AUTOSAR XML (schema 00046)
package /ComponentTypes
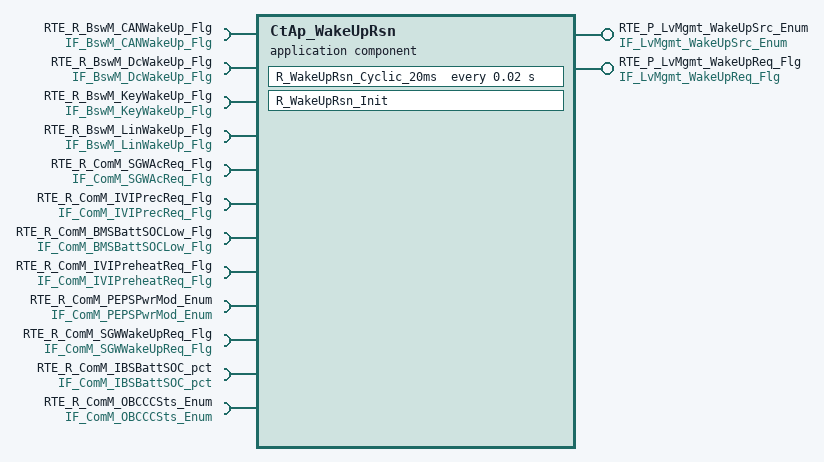
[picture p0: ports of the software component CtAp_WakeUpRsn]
  application sw component type CtAp_WakeUpRsn
    12 x require port:
      RTE_R_BswM_CANWakeUp_Flg: nonqueued-receiver-com-spec{data-element=tec_BswM_CANWakeUp_Flg, filter=data-filter-type=ALWAYS, init-value=0}, required-interface=IF_BswM_CANWakeUp_Flg
      RTE_R_BswM_DcWakeUp_Flg: nonqueued-receiver-com-spec{data-element=tec_BswM_DcWakeUp_Flg, filter=data-filter-type=ALWAYS, init-value=0}, required-interface=IF_BswM_DcWakeUp_Flg
      RTE_R_BswM_KeyWakeUp_Flg: nonqueued-receiver-com-spec{data-element=tec_BswM_KeyWakeUp_Flg, filter=data-filter-type=ALWAYS, init-value=0}, required-interface=IF_BswM_KeyWakeUp_Flg
      RTE_R_BswM_LinWakeUp_Flg: nonqueued-receiver-com-spec{data-element=tec_BswM_LinWakeUp_Flg, filter=data-filter-type=ALWAYS, init-value=0}, required-interface=IF_BswM_LinWakeUp_Flg
      RTE_R_ComM_SGWAcReq_Flg: nonqueued-receiver-com-spec{data-element=tec_ComM_SGWAcReq_Flg, filter=data-filter-type=ALWAYS, init-value=0}, required-interface=IF_ComM_SGWAcReq_Flg
      RTE_R_ComM_IVIPrecReq_Flg: nonqueued-receiver-com-spec{data-element=tec_ComM_IVIPrecReq_Flg, filter=data-filter-type=ALWAYS, init-value=0}, required-interface=IF_ComM_IVIPrecReq_Flg
      RTE_R_ComM_BMSBattSOCLow_Flg: nonqueued-receiver-com-spec{data-element=tec_ComM_BMSBattSOCLow_Flg, filter=data-filter-type=ALWAYS, init-value=0}, required-interface=IF_ComM_BMSBattSOCLow_Flg
      RTE_R_ComM_IVIPreheatReq_Flg: nonqueued-receiver-com-spec{data-element=tec_ComM_IVIPreheatReq_Flg, filter=data-filter-type=ALWAYS, init-value=0}, required-interface=IF_ComM_IVIPreheatReq_Flg
      RTE_R_ComM_PEPSPwrMod_Enum: nonqueued-receiver-com-spec{data-element=tec_ComM_PEPSPwrMod_Enum, filter=data-filter-type=ALWAYS, init-value=0}, required-interface=IF_ComM_PEPSPwrMod_Enum
      RTE_R_ComM_SGWWakeUpReq_Flg: nonqueued-receiver-com-spec{data-element=tec_ComM_SGWWakeUpReq_Flg, filter=data-filter-type=ALWAYS, init-value=0}, required-interface=IF_ComM_SGWWakeUpReq_Flg
      RTE_R_ComM_IBSBattSOC_pct: nonqueued-receiver-com-spec{data-element=tec_ComM_IBSBattSOC_pct, filter=data-filter-type=ALWAYS, init-value=0}, required-interface=IF_ComM_IBSBattSOC_pct
      RTE_R_ComM_OBCCCSts_Enum: nonqueued-receiver-com-spec{data-element=tec_ComM_OBCCCSts_Enum, filter=data-filter-type=ALWAYS, init-value=0}, required-interface=IF_ComM_OBCCCSts_Enum
    provide port RTE_P_LvMgmt_WakeUpSrc_Enum: nonqueued-sender-com-spec{data-element=tec_LvMgmt_WakeUpSrc_Enum, init-value=0}, provided-interface=IF_LvMgmt_WakeUpSrc_Enum
    provide port RTE_P_LvMgmt_WakeUpReq_Flg: nonqueued-sender-com-spec{data-element=tec_LvMgmt_WakeUpReq_Flg, init-value=0}, provided-interface=IF_LvMgmt_WakeUpReq_Flg
    behavior CtAp_WakeUpRsn_InternalBehavior
      init event CtAp_WakeUpRsn_InitEvent: start-on-event=R_WakeUpRsn_Init
      timing event TMT_R_WakeUpRsn_Cyclic_20ms: start-on-event=R_WakeUpRsn_Cyclic_20ms, period=0.02
      runnable R_WakeUpRsn_Init
      runnable R_WakeUpRsn_Cyclic_20ms
        data-receive-point-by-arguments:
          12 x access:
            REC_RTE_R_BswM_CANWakeUp_Flg_tec_BswM_CANWakeUp_Flg: accessed-variable=RTE_R_BswM_CANWakeUp_Flg.tec_BswM_CANWakeUp_Flg
            REC_RTE_R_BswM_DcWakeUp_Flg_tec_BswM_DcWakeUp_Flg: accessed-variable=RTE_R_BswM_DcWakeUp_Flg.tec_BswM_DcWakeUp_Flg
            REC_RTE_R_BswM_KeyWakeUp_Flg_tec_BswM_KeyWakeUp_Flg: accessed-variable=RTE_R_BswM_KeyWakeUp_Flg.tec_BswM_KeyWakeUp_Flg
            REC_RTE_R_BswM_LinWakeUp_Flg_tec_BswM_LinWakeUp_Flg: accessed-variable=RTE_R_BswM_LinWakeUp_Flg.tec_BswM_LinWakeUp_Flg
            REC_RTE_R_ComM_BMSBattSOCLow_Flg_tec_ComM_BMSBattSOCLow_Flg: accessed-variable=RTE_R_ComM_BMSBattSOCLow_Flg.tec_ComM_BMSBattSOCLow_Flg
            REC_RTE_R_ComM_IBSBattSOC_pct_tec_ComM_IBSBattSOC_pct: accessed-variable=RTE_R_ComM_IBSBattSOC_pct.tec_ComM_IBSBattSOC_pct
            REC_RTE_R_ComM_IVIPrecReq_Flg_tec_ComM_IVIPrecReq_Flg: accessed-variable=RTE_R_ComM_IVIPrecReq_Flg.tec_ComM_IVIPrecReq_Flg
            REC_RTE_R_ComM_IVIPreheatReq_Flg_tec_ComM_IVIPreheatReq_Flg: accessed-variable=RTE_R_ComM_IVIPreheatReq_Flg.tec_ComM_IVIPreheatReq_Flg
            REC_RTE_R_ComM_OBCCCSts_Enum_tec_ComM_OBCCCSts_Enum: accessed-variable=RTE_R_ComM_OBCCCSts_Enum.tec_ComM_OBCCCSts_Enum
            REC_RTE_R_ComM_PEPSPwrMod_Enum_tec_ComM_PEPSPwrMod_Enum: accessed-variable=RTE_R_ComM_PEPSPwrMod_Enum.tec_ComM_PEPSPwrMod_Enum
            REC_RTE_R_ComM_SGWAcReq_Flg_tec_ComM_SGWAcReq_Flg: accessed-variable=RTE_R_ComM_SGWAcReq_Flg.tec_ComM_SGWAcReq_Flg
            REC_RTE_R_ComM_SGWWakeUpReq_Flg_tec_ComM_SGWWakeUpReq_Flg: accessed-variable=RTE_R_ComM_SGWWakeUpReq_Flg.tec_ComM_SGWWakeUpReq_Flg
        data-send-points:
          access SEND_RTE_P_LvMgmt_WakeUpReq_Flg_tec_LvMgmt_WakeUpReq_Flg: accessed-variable=RTE_P_LvMgmt_WakeUpReq_Flg.tec_LvMgmt_WakeUpReq_Flg
          access SEND_RTE_P_LvMgmt_WakeUpSrc_Enum_tec_LvMgmt_WakeUpSrc_Enum: accessed-variable=RTE_P_LvMgmt_WakeUpSrc_Enum.tec_LvMgmt_WakeUpSrc_Enum
  swc implementation CtAp_WakeUpRsn_Implementation: behavior=CtAp_WakeUpRsn_InternalBehavior
    code-descriptors:
      code Default: artifact-descriptors=autosar-engineering-object=category=SWOBJ
